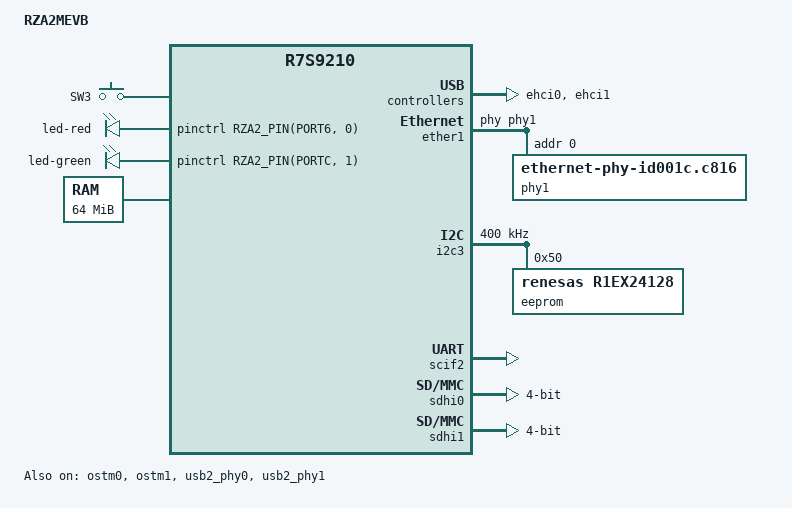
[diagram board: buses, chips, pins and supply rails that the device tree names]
/dts-v1/;
#include "r7s9210.dtsi"
#include <dt-bindings/gpio/gpio.h>
#include <dt-bindings/input/input.h>
#include <dt-bindings/pinctrl/r7s9210-pinctrl.h>
/ {
	model = "RZA2MEVB";
	compatible = "renesas,rza2mevb", "renesas,r7s9210";
	aliases {
		serial0 = &scif2;
		ethernet0 = &ether1;
	};
	chosen {
		bootargs = "ignore_loglevel";
		stdout-path = "serial0:115200n8";
	};
	keyboard {
		compatible = "gpio-keys";
		pinctrl-names = "default";
		pinctrl-0 = <&keyboard_pins>;
		key-3 {
			interrupt-parent = <&irqc>;
			interrupts = <0 IRQ_TYPE_EDGE_BOTH>;
			linux,code = <KEY_3>;
			label = "SW3";
			wakeup-source;
		};
	};
	lbsc {
		#address-cells = <1>;
		#size-cells = <1>;
	};
	leds {
		compatible = "gpio-leds";
		led-red {
			gpios = <&pinctrl RZA2_PIN(PORT6, 0) GPIO_ACTIVE_HIGH>;
		};
		led-green {
			gpios = <&pinctrl RZA2_PIN(PORTC, 1) GPIO_ACTIVE_HIGH>;
		};
	};
	memory@c000000 {
		device_type = "memory";
		reg = <0x0c000000 0x04000000>;	 
	};
};
&ehci0 {
	status = "okay";
};
&ehci1 {
	status = "okay";
};
&ether1 {
	pinctrl-names = "default";
	pinctrl-0 = <&eth1_pins>;
	status = "okay";
	renesas,no-ether-link;
	phy-handle = <&phy1>;
	phy1: ethernet-phy@1 {
		compatible = "ethernet-phy-id001c.c816",
			     "ethernet-phy-ieee802.3-c22";
		reg = <0>;
	};
};
&extal_clk {
	clock-frequency = <24000000>;	 
};
&i2c3 {
	status = "okay";
	clock-frequency = <400000>;
	pinctrl-names = "default";
	pinctrl-0 = <&i2c3_pins>;
	eeprom@50 {
		compatible = "renesas,r1ex24128", "atmel,24c128";
		reg = <0x50>;
		pagesize = <64>;
	};
};
&ostm0 {
	status = "okay";
};
&ostm1 {
	status = "okay";
};
&pinctrl {
	eth0_pins: eth0 {
		pinmux = <RZA2_PINMUX(PORTE, 0, 7)>,  
			 <RZA2_PINMUX(PORT6, 1, 7)>,  
			 <RZA2_PINMUX(PORT6, 2, 7)>,  
			 <RZA2_PINMUX(PORT6, 3, 7)>,  
			 <RZA2_PINMUX(PORTE, 4, 7)>,  
			 <RZA2_PINMUX(PORTE, 1, 7)>,  
			 <RZA2_PINMUX(PORTE, 2, 7)>,  
			 <RZA2_PINMUX(PORTE, 3, 7)>,  
			 <RZA2_PINMUX(PORTE, 5, 1)>,  
			 <RZA2_PINMUX(PORTE, 6, 1)>,  
			 <RZA2_PINMUX(PORTL, 0, 5)>;  
	};
	eth1_pins: eth1 {
		pinmux = <RZA2_PINMUX(PORTK, 3, 7)>,  
			 <RZA2_PINMUX(PORTK, 0, 7)>,  
			 <RZA2_PINMUX(PORTK, 1, 7)>,  
			 <RZA2_PINMUX(PORTK, 2, 7)>,  
			 <RZA2_PINMUX(PORT3, 2, 7)>,  
			 <RZA2_PINMUX(PORTK, 4, 7)>,  
			 <RZA2_PINMUX(PORT3, 5, 7)>,  
			 <RZA2_PINMUX(PORT3, 1, 7)>,  
			 <RZA2_PINMUX(PORT3, 3, 1)>,  
			 <RZA2_PINMUX(PORT3, 4, 1)>,  
			 <RZA2_PINMUX(PORTL, 1, 5)>;  
	};
	i2c3_pins: i2c3 {
		pinmux = <RZA2_PINMUX(PORTD, 6, 1)>,	 
			 <RZA2_PINMUX(PORTD, 7, 1)>;	 
	};
	keyboard_pins: keyboard {
		pinmux = <RZA2_PINMUX(PORTJ, 1, 6)>;	 
	};
	scif2_pins: serial2 {
		pinmux = <RZA2_PINMUX(PORTE, 2, 3)>,	 
			 <RZA2_PINMUX(PORTE, 1, 3)>;	 
	};
	sdhi0_pins: sdhi0 {
		pinmux = <RZA2_PINMUX(PORT5, 0, 3)>,	 
			 <RZA2_PINMUX(PORT5, 1, 3)>;	 
	};
	sdhi1_pins: sdhi1 {
		pinmux = <RZA2_PINMUX(PORT5, 4, 3)>,	 
			 <RZA2_PINMUX(PORT5, 5, 3)>;	 
	};
	usb0_pins: usb0 {
		pinmux = <RZA2_PINMUX(PORT5, 2, 3)>,	 
			 <RZA2_PINMUX(PORTC, 6, 1)>,	 
			 <RZA2_PINMUX(PORTC, 7, 1)>;	 
	};
	usb1_pins: usb1 {
		pinmux = <RZA2_PINMUX(PORTC, 0, 1)>,	 
			 <RZA2_PINMUX(PORTC, 5, 1)>;	 
	};
};
&rtc_x1_clk {
	clock-frequency = <32768>;
};
&scif2 {
	pinctrl-names = "default";
	pinctrl-0 = <&scif2_pins>;
	status = "okay";
};
&sdhi0 {
	pinctrl-names = "default";
	pinctrl-0 = <&sdhi0_pins>;
	bus-width = <4>;
	status = "okay";
};
&sdhi1 {
	pinctrl-names = "default";
	pinctrl-0 = <&sdhi1_pins>;
	bus-width = <4>;
	status = "okay";
};
&usb2_phy0 {
	pinctrl-names = "default";
	pinctrl-0 = <&usb0_pins>;
	dr_mode = "host";	 
	status = "okay";
};
&usb2_phy1 {
	pinctrl-names = "default";
	pinctrl-0 = <&usb1_pins>;
	dr_mode = "host";
	status = "okay";
};
&usb_x1_clk {
	clock-frequency = <48000000>;
};
